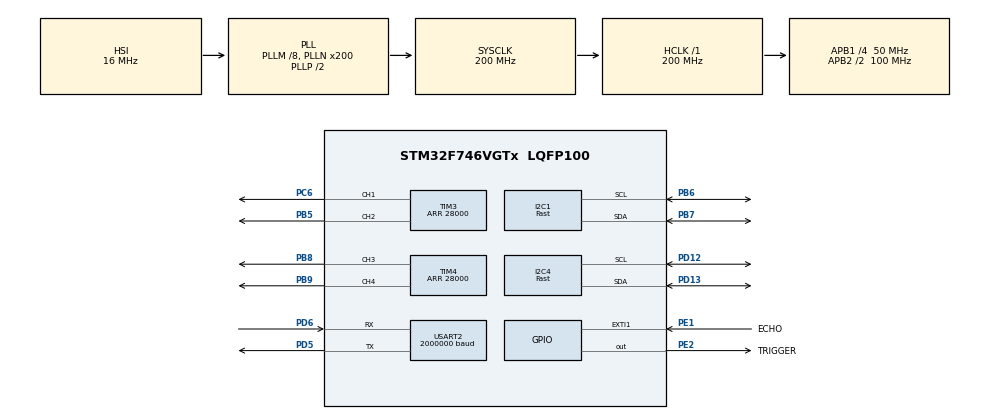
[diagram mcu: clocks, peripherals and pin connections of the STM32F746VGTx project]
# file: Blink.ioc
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CORTEX_M7.ART_ACCLERATOR_ENABLE=1
CORTEX_M7.CPU_DCache=Enabled
CORTEX_M7.CPU_ICache=Enabled
CORTEX_M7.PREFETCH_ENABLE=1
I2C1.I2C_Speed_Mode=I2C_Fast
I2C1.Timing=0x00401959
I2C4.I2C_Speed_Mode=I2C_Fast
I2C4.OwnAddress=0x60
I2C4.Timing=0x00401959
Mcu.Family=STM32F7
Mcu.Name=STM32F746VGTx
Mcu.Package=LQFP100
NVIC.EXTI1_IRQn=true\:0\:0\:false\:false\:true\:true\:true
NVIC.I2C4_EV_IRQn=true\:0\:0\:false\:false\:true\:true\:true
NVIC.PriorityGroup=NVIC_PRIORITYGROUP_4
NVIC.USART2_IRQn=true\:0\:0\:false\:false\:true\:true\:true
PB5.GPIO_ModeDefaultPP=GPIO_MODE_AF_OD
PB5.GPIO_Speed=GPIO_SPEED_FREQ_VERY_HIGH
PB5.Signal=S_TIM3_CH2
PB6.Mode=I2C
PB6.Signal=I2C1_SCL
PB7.Mode=I2C
PB7.Signal=I2C1_SDA
PB8.GPIO_ModeDefaultPP=GPIO_MODE_AF_OD
PB8.GPIO_Speed=GPIO_SPEED_FREQ_VERY_HIGH
PB8.Signal=S_TIM4_CH3
PB9.GPIO_ModeDefaultPP=GPIO_MODE_AF_OD
PB9.GPIO_Speed=GPIO_SPEED_FREQ_VERY_HIGH
PB9.Signal=S_TIM4_CH4
PC6.GPIO_ModeDefaultPP=GPIO_MODE_AF_OD
PC6.GPIO_Speed=GPIO_SPEED_FREQ_VERY_HIGH
PC6.Signal=S_TIM3_CH1
PD12.GPIO_PuPdOD=GPIO_NOPULL
PD12.Mode=I2C
PD12.Signal=I2C4_SCL
PD13.GPIO_PuPdOD=GPIO_NOPULL
PD13.Mode=I2C
PD13.Signal=I2C4_SDA
PD5.Mode=Asynchronous
PD5.Signal=USART2_TX
PD6.Mode=Asynchronous
PD6.Signal=USART2_RX
PE1.GPIO_Label=ECHO
PE1.GPIO_ModeDefaultEXTI=GPIO_MODE_IT_RISING_FALLING
PE1.Signal=GPXTI1
PE2.GPIO_Label=TRIGGER
PE2.GPIO_Speed=GPIO_SPEED_FREQ_HIGH
PE2.PinState=GPIO_PIN_RESET
PE2.Signal=GPIO_Output
ProjectManager.HeapSize=0x200
ProjectManager.StackSize=0x400
ProjectManager.TargetToolchain=Makefile
RCC.AHBFreq_Value=200000000
RCC.APB1CLKDivider=RCC_HCLK_DIV4
RCC.APB1Freq_Value=50000000
RCC.APB1TimFreq_Value=100000000
RCC.APB2CLKDivider=RCC_HCLK_DIV2
RCC.APB2Freq_Value=100000000
RCC.APB2TimFreq_Value=200000000
RCC.CortexFreq_Value=200000000
RCC.HCLKFreq_Value=200000000
RCC.HSE_VALUE=25000000
RCC.HSI_VALUE=16000000
RCC.LSE_VALUE=32768
RCC.PLLM=8
RCC.PLLN=200
RCC.SYSCLKFreq_VALUE=200000000
RCC.SYSCLKSource=RCC_SYSCLKSOURCE_PLLCLK
RCC.USBFreq_Value=200000000
RCC.VCOOutputFreq_Value=400000000
SH.S_TIM3_CH1.0=TIM3_CH1,PWM Generation1 CH1
SH.S_TIM3_CH2.0=TIM3_CH2,PWM Generation2 CH2
SH.S_TIM4_CH3.0=TIM4_CH3,PWM Generation3 CH3
SH.S_TIM4_CH4.0=TIM4_CH4,PWM Generation4 CH4
TIM3.Channel-PWM\ Generation1\ CH1=TIM_CHANNEL_1
TIM3.Channel-PWM\ Generation2\ CH2=TIM_CHANNEL_2
TIM3.OCFastMode_PWM-PWM\ Generation1\ CH1=TIM_OCFAST_ENABLE
TIM3.OCFastMode_PWM-PWM\ Generation2\ CH2=TIM_OCFAST_ENABLE
TIM3.Period=28000
TIM4.Channel-PWM\ Generation3\ CH3=TIM_CHANNEL_3
TIM4.Channel-PWM\ Generation4\ CH4=TIM_CHANNEL_4
TIM4.OCFastMode_PWM-PWM\ Generation3\ CH3=TIM_OCFAST_ENABLE
TIM4.OCFastMode_PWM-PWM\ Generation4\ CH4=TIM_OCFAST_ENABLE
TIM4.Period=28000
TIM5.Prescaler=100
USART2.BaudRate=2000000
USART2.SwapParam=ADVFEATURE_SWAP_DISABLE
USART2.VirtualMode-Asynchronous=VM_ASYNC
VP_TIM3_VS_ClockSourceINT.Mode=Internal
VP_TIM4_VS_ClockSourceINT.Mode=Internal
VP_TIM5_VS_ClockSourceINT.Mode=Internal
board=custom

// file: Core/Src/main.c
/* USER CODE BEGIN Header */
/**
  ******************************************************************************
  * @file           : main.c
  * @brief          : Main program body
  ******************************************************************************
  * @attention
  *
  * <h2><center>&copy; Copyright (c) 2021 STMicroelectronics.
  * All rights reserved.</center></h2>
  *
  * This software component is licensed by ST under BSD 3-Clause license,
  * the "License"; You may not use this file except in compliance with the
  * License. You may obtain a copy of the License at:
  *                        opensource.org/licenses/BSD-3-Clause
  *
  ******************************************************************************
  */
/* USER CODE END Header */
#include "main.h"
#include "i2c.h"
#include "tim.h"
#include "usart.h"
#include "gpio.h"

void SystemClock_Config(void);

int main(void)
{
  /* USER CODE BEGIN 1 */
  #if (__FPU_PRESENT == 1) && (__FPU_USED == 1)
    SCB->CPACR |= ((3UL << 10*2)|(3UL << 11*2));  /* set CP10 and CP11 Full Access */
  #endif
  /* USER CODE END 1 */

  /* Enable I-Cache---------------------------------------------------------*/
  SCB_EnableICache();

  /* Enable D-Cache---------------------------------------------------------*/
  SCB_EnableDCache();

  /* MCU Configuration--------------------------------------------------------*/

  /* Reset of all peripherals, Initializes the Flash interface and the Systick. */
  HAL_Init();

  /* Configure the system clock */
  SystemClock_Config();

  /* Initialize all configured peripherals */
  MX_GPIO_Init();
  MX_I2C1_Init();
  MX_I2C4_Init();
  #if PORT == DEBUG || PORT == GPS || PORT == FLOW
    MX_USART2_UART_Init();
  #endif
  MX_TIM3_Init();
  MX_TIM4_Init();
  MX_TIM5_Init();
  /* USER CODE BEGIN 2 */
  HAL_TIM_Base_Start(&htim5);
  _main();
  /* USER CODE END 2 */

  /* Infinite loop */
  while (1)
  {

  }
}

void SystemClock_Config(void)
{
  RCC_OscInitTypeDef RCC_OscInitStruct = {0};
  RCC_ClkInitTypeDef RCC_ClkInitStruct = {0};
  RCC_PeriphCLKInitTypeDef PeriphClkInitStruct = {0};

  /** Configure the main internal regulator output voltage
  */
  __HAL_RCC_PWR_CLK_ENABLE();
  __HAL_PWR_VOLTAGESCALING_CONFIG(PWR_REGULATOR_VOLTAGE_SCALE1);
  /** Initializes the RCC Oscillators according to the specified parameters
  * in the RCC_OscInitTypeDef structure.
  */
  RCC_OscInitStruct.OscillatorType = RCC_OSCILLATORTYPE_HSI;
  RCC_OscInitStruct.HSIState = RCC_HSI_ON;
  RCC_OscInitStruct.HSICalibrationValue = RCC_HSICALIBRATION_DEFAULT;
  RCC_OscInitStruct.PLL.PLLState = RCC_PLL_ON;
  RCC_OscInitStruct.PLL.PLLSource = RCC_PLLSOURCE_HSI;
  RCC_OscInitStruct.PLL.PLLM = 8;
  RCC_OscInitStruct.PLL.PLLN = 200;
  RCC_OscInitStruct.PLL.PLLP = RCC_PLLP_DIV2;
  RCC_OscInitStruct.PLL.PLLQ = 2;
  if (HAL_RCC_OscConfig(&RCC_OscInitStruct) != HAL_OK)
  {
    Error_Handler();
  }
  /** Activate the Over-Drive mode
  */
  if (HAL_PWREx_EnableOverDrive() != HAL_OK)
  {
    Error_Handler();
  }
  /** Initializes the CPU, AHB and APB buses clocks
  */
  RCC_ClkInitStruct.ClockType = RCC_CLOCKTYPE_HCLK|RCC_CLOCKTYPE_SYSCLK
                              |RCC_CLOCKTYPE_PCLK1|RCC_CLOCKTYPE_PCLK2;
  RCC_ClkInitStruct.SYSCLKSource = RCC_SYSCLKSOURCE_PLLCLK;
  RCC_ClkInitStruct.AHBCLKDivider = RCC_SYSCLK_DIV1;
  RCC_ClkInitStruct.APB1CLKDivider = RCC_HCLK_DIV4;
  RCC_ClkInitStruct.APB2CLKDivider = RCC_HCLK_DIV2;

  if (HAL_RCC_ClockConfig(&RCC_ClkInitStruct, FLASH_LATENCY_6) != HAL_OK)
  {
    Error_Handler();
  }
  PeriphClkInitStruct.PeriphClockSelection = RCC_PERIPHCLK_USART2|RCC_PERIPHCLK_I2C1
                              |RCC_PERIPHCLK_I2C4;
  PeriphClkInitStruct.Usart2ClockSelection = RCC_USART2CLKSOURCE_PCLK1;
  PeriphClkInitStruct.I2c1ClockSelection = RCC_I2C1CLKSOURCE_PCLK1;
  PeriphClkInitStruct.I2c4ClockSelection = RCC_I2C4CLKSOURCE_PCLK1;
  if (HAL_RCCEx_PeriphCLKConfig(&PeriphClkInitStruct) != HAL_OK)
  {
    Error_Handler();
  }
}

void Error_Handler(void)
{
  __disable_irq();
  while (1)
  {
  }
}

/************************ (C) COPYRIGHT STMicroelectronics *****END OF FILE****/
